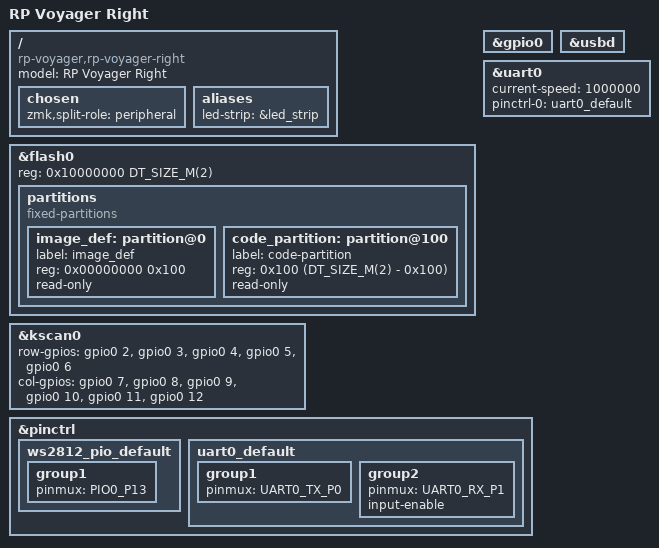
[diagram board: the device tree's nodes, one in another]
/dts-v1/;
#include <raspberrypi/rpi_pico/rp2350a.dtsi>
#include <raspberrypi/rpi_pico/m33.dtsi>
#include <dt-bindings/led/led.h>
#include <dt-bindings/pinctrl/rpi-pico-rp2350a-pinctrl.h>
#include "../common/rp_voyager_common.dtsi"

/ {
	model = "RP Voyager Right";
	compatible = "rp-voyager,rp-voyager-right";

    chosen {
        zmk,split-role = "peripheral";
    };

	aliases {
		led-strip = &led_strip;
	};
};

&flash0 {
	reg = <0x10000000 DT_SIZE_M(2)>;
	partitions {
		compatible = "fixed-partitions";
		#address-cells = <1>;
		#size-cells = <1>;
		image_def: partition@0 {
			label = "image_def";
			reg = <0x00000000 0x100>;
			read-only;
		};
		code_partition: partition@100 {
			label = "code-partition";
			reg = <0x100 (DT_SIZE_M(2) - 0x100)>;
			read-only;
		};
	};
};

&gpio0 {
	status = "okay";
};

zephyr_udc0: &usbd {
	status = "okay";
};

&kscan0 {
	row-gpios
		= <&gpio0 2 (GPIO_ACTIVE_HIGH | GPIO_PULL_DOWN)>  /* row 0 */
		, <&gpio0 3 (GPIO_ACTIVE_HIGH | GPIO_PULL_DOWN)>  /* row 1 */
		, <&gpio0 4 (GPIO_ACTIVE_HIGH | GPIO_PULL_DOWN)>  /* row 2 */
		, <&gpio0 5 (GPIO_ACTIVE_HIGH | GPIO_PULL_DOWN)>  /* row 3 */
		, <&gpio0 6 (GPIO_ACTIVE_HIGH | GPIO_PULL_DOWN)>  /* row 4 (thumb) */
		;
	col-gpios
		= <&gpio0 7  GPIO_ACTIVE_HIGH>  /* col 0 */
		, <&gpio0 8  GPIO_ACTIVE_HIGH>  /* col 1 */
		, <&gpio0 9  GPIO_ACTIVE_HIGH>  /* col 2 */
		, <&gpio0 10 GPIO_ACTIVE_HIGH>  /* col 3 */
		, <&gpio0 11 GPIO_ACTIVE_HIGH>  /* col 4 */
		, <&gpio0 12 GPIO_ACTIVE_HIGH>  /* col 5 */
		;
};

&uart0 {
	status = "okay";
	current-speed = <1000000>;
	pinctrl-0 = <&uart0_default>;
	pinctrl-names = "default";
};

&pinctrl {
    ws2812_pio_default: ws2812_pio_default {
        group1 {
            pinmux = <PIO0_P13>;
        };
    };
	uart0_default: uart0_default {
		group1 {
			pinmux = <UART0_TX_P0>; /* or P12 / P16 / P28 */
		};
		group2 {
            pinmux = <UART0_RX_P1>; /* or P13 / P17 / P29 */
            input-enable;
        };
	};
};
